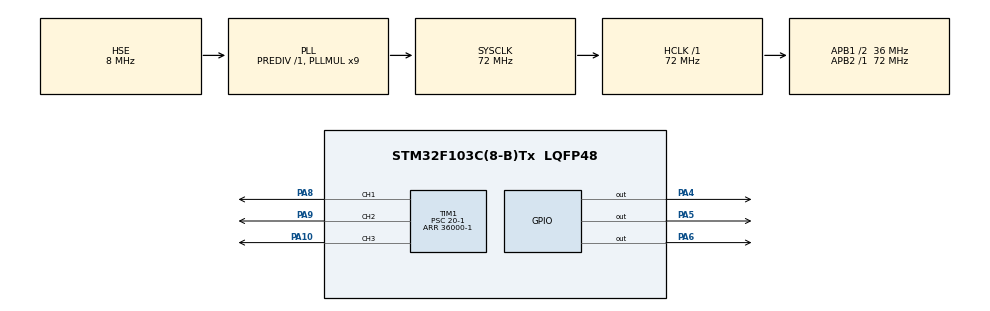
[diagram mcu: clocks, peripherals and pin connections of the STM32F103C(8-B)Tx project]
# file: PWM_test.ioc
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Mcu.Family=STM32F1
Mcu.Name=STM32F103C(8-B)Tx
Mcu.Package=LQFP48
NVIC.PriorityGroup=NVIC_PRIORITYGROUP_4
PA10.Signal=S_TIM1_CH3
PA13.Mode=Serial_Wire
PA13.Signal=SYS_JTMS-SWDIO
PA14.Mode=Serial_Wire
PA14.Signal=SYS_JTCK-SWCLK
PA4.Signal=GPIO_Output
PA5.Signal=GPIO_Output
PA6.Signal=GPIO_Output
PA8.Signal=S_TIM1_CH1
PA9.Signal=S_TIM1_CH2
PD0-OSC_IN.Mode=HSE-External-Oscillator
PD0-OSC_IN.Signal=RCC_OSC_IN
PD1-OSC_OUT.Mode=HSE-External-Oscillator
PD1-OSC_OUT.Signal=RCC_OSC_OUT
ProjectManager.HeapSize=0x200
ProjectManager.StackSize=0x400
ProjectManager.TargetToolchain=STM32CubeIDE
RCC.AHBFreq_Value=72000000
RCC.APB1CLKDivider=RCC_HCLK_DIV2
RCC.APB1Freq_Value=36000000
RCC.APB1TimFreq_Value=72000000
RCC.APB2Freq_Value=72000000
RCC.APB2TimFreq_Value=72000000
RCC.HCLKFreq_Value=72000000
RCC.PLLMUL=RCC_PLL_MUL9
RCC.PLLSourceVirtual=RCC_PLLSOURCE_HSE
RCC.SYSCLKFreq_VALUE=72000000
RCC.SYSCLKSource=RCC_SYSCLKSOURCE_PLLCLK
RCC.USBFreq_Value=72000000
SH.S_TIM1_CH1.0=TIM1_CH1,PWM Generation1 CH1
SH.S_TIM1_CH2.0=TIM1_CH2,PWM Generation2 CH2
SH.S_TIM1_CH3.0=TIM1_CH3,Output Compare3 CH3
TIM1.Channel-Output\ Compare3\ CH3=TIM_CHANNEL_3
TIM1.Channel-PWM\ Generation1\ CH1=TIM_CHANNEL_1
TIM1.Channel-PWM\ Generation2\ CH2=TIM_CHANNEL_2
TIM1.Channel-PWM\ Generation3\ CH3=TIM_CHANNEL_3
TIM1.Period=36000-1
TIM1.Prescaler=20-1
TIM1.Pulse-Output\ Compare3\ CH3=5250-1
TIM1.Pulse-PWM\ Generation1\ CH1=21000-1
TIM1.Pulse-PWM\ Generation2\ CH2=10500-1
VP_TIM1_VS_ClockSourceINT.Mode=Internal
board=custom

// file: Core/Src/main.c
/* USER CODE BEGIN Header */
/**
  ******************************************************************************
  * @file           : main.c
  * @brief          : Main program body
  ******************************************************************************
  * @attention
  *
  * Copyright (c) 2023 STMicroelectronics.
  * All rights reserved.
  *
  * This software is licensed under terms that can be found in the LICENSE file
  * in the root directory of this software component.
  * If no LICENSE file comes with this software, it is provided AS-IS.
  *
  ******************************************************************************
  */
/* USER CODE END Header */
#include "main.h"

TIM_HandleTypeDef htim1;

void SystemClock_Config(void);
static void MX_GPIO_Init(void);
static void MX_TIM1_Init(void);

int main(void)
{

  /* MCU Configuration--------------------------------------------------------*/

  /* Reset of all peripherals, Initializes the Flash interface and the Systick. */
  HAL_Init();

  /* Configure the system clock */
  SystemClock_Config();

  /* Initialize all configured peripherals */
  MX_GPIO_Init();
  MX_TIM1_Init();
  /* USER CODE BEGIN 2 */
  HAL_TIM_PWM_Start(&htim1, TIM_CHANNEL_1);
  HAL_TIM_PWM_Start(&htim1, TIM_CHANNEL_2);
  HAL_TIM_PWM_Start(&htim1, TIM_CHANNEL_3);

  uint16_t ccr = 0;

  /* USER CODE END 2 */

  /* Infinite loop */
  while (1)
  {

    /* USER CODE BEGIN 3 */
	  __HAL_TIM_SET_COMPARE(&htim1, TIM_CHANNEL_1, ccr);
	  //TIM1 -> CCR1 = ccr;
	  ccr += 1000;
	  if(ccr > TIM1->ARR) ccr = 0; //auto reload register를 넘어가면 다시 0부터
	  HAL_Delay(50);
  }
  /* USER CODE END 3 */
}

void SystemClock_Config(void)
{
  RCC_OscInitTypeDef RCC_OscInitStruct = {0};
  RCC_ClkInitTypeDef RCC_ClkInitStruct = {0};

  /** Initializes the RCC Oscillators according to the specified parameters
  * in the RCC_OscInitTypeDef structure.
  */
  RCC_OscInitStruct.OscillatorType = RCC_OSCILLATORTYPE_HSE;
  RCC_OscInitStruct.HSEState = RCC_HSE_ON;
  RCC_OscInitStruct.HSEPredivValue = RCC_HSE_PREDIV_DIV1;
  RCC_OscInitStruct.HSIState = RCC_HSI_ON;
  RCC_OscInitStruct.PLL.PLLState = RCC_PLL_ON;
  RCC_OscInitStruct.PLL.PLLSource = RCC_PLLSOURCE_HSE;
  RCC_OscInitStruct.PLL.PLLMUL = RCC_PLL_MUL9;
  if (HAL_RCC_OscConfig(&RCC_OscInitStruct) != HAL_OK)
  {
    Error_Handler();
  }

  /** Initializes the CPU, AHB and APB buses clocks
  */
  RCC_ClkInitStruct.ClockType = RCC_CLOCKTYPE_HCLK|RCC_CLOCKTYPE_SYSCLK
                              |RCC_CLOCKTYPE_PCLK1|RCC_CLOCKTYPE_PCLK2;
  RCC_ClkInitStruct.SYSCLKSource = RCC_SYSCLKSOURCE_PLLCLK;
  RCC_ClkInitStruct.AHBCLKDivider = RCC_SYSCLK_DIV1;
  RCC_ClkInitStruct.APB1CLKDivider = RCC_HCLK_DIV2;
  RCC_ClkInitStruct.APB2CLKDivider = RCC_HCLK_DIV1;

  if (HAL_RCC_ClockConfig(&RCC_ClkInitStruct, FLASH_LATENCY_2) != HAL_OK)
  {
    Error_Handler();
  }
}

static void MX_TIM1_Init(void)
{

  TIM_ClockConfigTypeDef sClockSourceConfig = {0};
  TIM_MasterConfigTypeDef sMasterConfig = {0};
  TIM_OC_InitTypeDef sConfigOC = {0};
  TIM_BreakDeadTimeConfigTypeDef sBreakDeadTimeConfig = {0};

  htim1.Instance = TIM1;
  htim1.Init.Prescaler = 20-1;
  htim1.Init.CounterMode = TIM_COUNTERMODE_UP;
  htim1.Init.Period = 36000-1;
  htim1.Init.ClockDivision = TIM_CLOCKDIVISION_DIV1;
  htim1.Init.RepetitionCounter = 0;
  htim1.Init.AutoReloadPreload = TIM_AUTORELOAD_PRELOAD_DISABLE;
  if (HAL_TIM_Base_Init(&htim1) != HAL_OK)
  {
    Error_Handler();
  }
  sClockSourceConfig.ClockSource = TIM_CLOCKSOURCE_INTERNAL;
  if (HAL_TIM_ConfigClockSource(&htim1, &sClockSourceConfig) != HAL_OK)
  {
    Error_Handler();
  }
  if (HAL_TIM_PWM_Init(&htim1) != HAL_OK)
  {
    Error_Handler();
  }
  if (HAL_TIM_OC_Init(&htim1) != HAL_OK)
  {
    Error_Handler();
  }
  sMasterConfig.MasterOutputTrigger = TIM_TRGO_RESET;
  sMasterConfig.MasterSlaveMode = TIM_MASTERSLAVEMODE_DISABLE;
  if (HAL_TIMEx_MasterConfigSynchronization(&htim1, &sMasterConfig) != HAL_OK)
  {
    Error_Handler();
  }
  sConfigOC.OCMode = TIM_OCMODE_PWM1;
  sConfigOC.Pulse = 21000-1;
  sConfigOC.OCPolarity = TIM_OCPOLARITY_HIGH;
  sConfigOC.OCNPolarity = TIM_OCNPOLARITY_HIGH;
  sConfigOC.OCFastMode = TIM_OCFAST_DISABLE;
  sConfigOC.OCIdleState = TIM_OCIDLESTATE_RESET;
  sConfigOC.OCNIdleState = TIM_OCNIDLESTATE_RESET;
  if (HAL_TIM_PWM_ConfigChannel(&htim1, &sConfigOC, TIM_CHANNEL_1) != HAL_OK)
  {
    Error_Handler();
  }
  sConfigOC.Pulse = 10500-1;
  if (HAL_TIM_PWM_ConfigChannel(&htim1, &sConfigOC, TIM_CHANNEL_2) != HAL_OK)
  {
    Error_Handler();
  }
  sConfigOC.OCMode = TIM_OCMODE_TIMING;
  sConfigOC.Pulse = 5250-1;
  if (HAL_TIM_OC_ConfigChannel(&htim1, &sConfigOC, TIM_CHANNEL_3) != HAL_OK)
  {
    Error_Handler();
  }
  sBreakDeadTimeConfig.OffStateRunMode = TIM_OSSR_DISABLE;
  sBreakDeadTimeConfig.OffStateIDLEMode = TIM_OSSI_DISABLE;
  sBreakDeadTimeConfig.LockLevel = TIM_LOCKLEVEL_OFF;
  sBreakDeadTimeConfig.DeadTime = 0;
  sBreakDeadTimeConfig.BreakState = TIM_BREAK_DISABLE;
  sBreakDeadTimeConfig.BreakPolarity = TIM_BREAKPOLARITY_HIGH;
  sBreakDeadTimeConfig.AutomaticOutput = TIM_AUTOMATICOUTPUT_DISABLE;
  if (HAL_TIMEx_ConfigBreakDeadTime(&htim1, &sBreakDeadTimeConfig) != HAL_OK)
  {
    Error_Handler();
  }
  HAL_TIM_MspPostInit(&htim1);

}

static void MX_GPIO_Init(void)
{
  GPIO_InitTypeDef GPIO_InitStruct = {0};

  /* GPIO Ports Clock Enable */
  __HAL_RCC_GPIOD_CLK_ENABLE();
  __HAL_RCC_GPIOA_CLK_ENABLE();

  /*Configure GPIO pin Output Level */
  HAL_GPIO_WritePin(GPIOA, GPIO_PIN_4|GPIO_PIN_5|GPIO_PIN_6, GPIO_PIN_RESET);

  /*Configure GPIO pins : PA4 PA5 PA6 */
  GPIO_InitStruct.Pin = GPIO_PIN_4|GPIO_PIN_5|GPIO_PIN_6;
  GPIO_InitStruct.Mode = GPIO_MODE_OUTPUT_PP;
  GPIO_InitStruct.Pull = GPIO_NOPULL;
  GPIO_InitStruct.Speed = GPIO_SPEED_FREQ_LOW;
  HAL_GPIO_Init(GPIOA, &GPIO_InitStruct);

}

void Error_Handler(void)
{
  __disable_irq();
  while (1)
  {
  }
}
